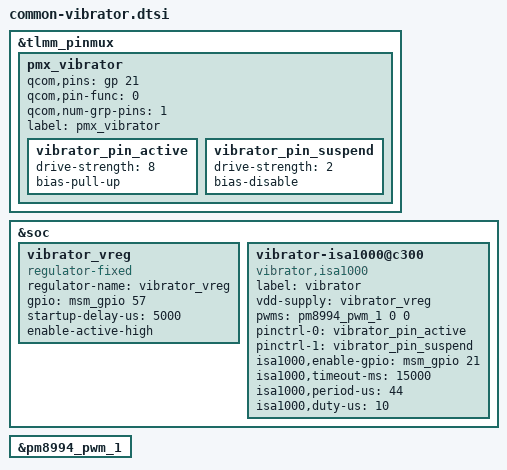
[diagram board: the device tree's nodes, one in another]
/* Copyright (c) 2017, The Linux Foundation. All rights reserved.
 *
 * This program is free software; you can redistribute it and/or modify
 * it under the terms of the GNU General Public License version 2 and
 * only version 2 as published by the Free Software Foundation.
 *
 * This program is distributed in the hope that it will be useful,
 * but WITHOUT ANY WARRANTY; without even the implied warranty of
 * MERCHANTABILITY or FITNESS FOR A PARTICULAR PURPOSE.  See the
 * GNU General Public License for more details.
 */

&tlmm_pinmux {
	pmx_vibrator {
		qcom,pins = <&gp 21>;
		qcom,pin-func = <0>;
		qcom,num-grp-pins = <1>;
		label = "pmx_vibrator";

		vibrator_pin_active: vibrator_pin_active {
			drive-strength = <8>;
			bias-pull-up;
		};

		vibrator_pin_suspend: vibrator_pin_suspend {
			drive-strength = <2>;
			bias-disable;
		};
	};
};

&soc {
	vibrator_vreg: vibrator_vreg {
		compatible = "regulator-fixed";
		regulator-name = "vibrator_vreg";
		gpio = <&msm_gpio 57 0>;
		startup-delay-us = <5000>;
		enable-active-high;
	};

	vibrator-isa1000@c300 {
		status = "okay";
		compatible = "vibrator,isa1000";
		label = "vibrator";
		vdd-supply = <&vibrator_vreg>;
		pwms = <&pm8994_pwm_1 0 0>;
		pinctrl-names = "vibrator_pin_active", "vibrator_pin_suspend";
		pinctrl-0 = <&vibrator_pin_active>;
		pinctrl-1 = <&vibrator_pin_suspend>;
		isa1000,enable-gpio = <&msm_gpio 21 0x00>;
		isa1000,timeout-ms = <15000>;
		isa1000,period-us = <44>;
		isa1000,duty-us = <10>;
	};
};

&pm8994_pwm_1 {
	status = "okay";
};
